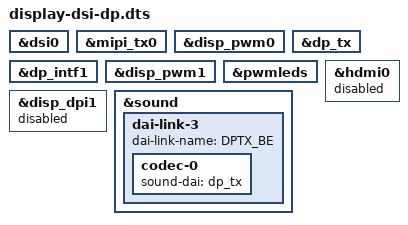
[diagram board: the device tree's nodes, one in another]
/dts-v1/;
/plugin/;

/ {
	fragment@0 {
		target = <&dsi0>;
		__overlay__ {
			status = "okay";
		};
	};

	fragment@1 {
		target = <&mipi_tx0>;
		__overlay__ {
			status = "okay";
		};
	};

	fragment@2 {
		target = <&disp_pwm0>;
		__overlay__ {
			status = "okay";
		};
	};

	fragment@3 {
		target = <&dp_tx>;
		__overlay__ {
			status = "okay";
		};
	};

	fragment@4 {
		target = <&dp_intf1>;
		__overlay__ {
			status = "okay";
		};
	};

	fragment@5 {
		target = <&disp_pwm1>;
		__overlay__ {
			status = "okay";
		};
	};

	fragment@6 {
		target = <&pwmleds>;
		__overlay__ {
			status = "okay";
		};
	};

	fragment@7 {
		target = <&disp_dpi1>;
		__overlay__ {
			status = "disabled";
		};
	};

	fragment@8 {
		target = <&hdmi0>;
		__overlay__ {
			status = "disabled";
		};
	};

	fragment@9 {
		target = <&sound>;
		__overlay__ {
			dai-link-3 {
				dai-link-name = "DPTX_BE";

				codec-0 {
					sound-dai = <&dp_tx>;
				};
			};
		};
	};
};
